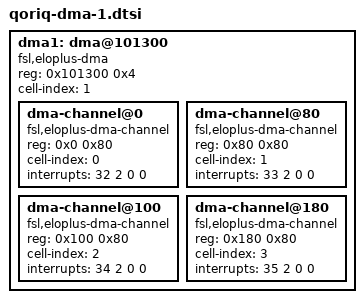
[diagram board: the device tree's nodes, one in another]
/*
 * QorIQ DMA device tree stub [ controller @ offset 0x101000 ]
 *
 * Copyright 2011 Freescale Semiconductor Inc.
 *
 * Redistribution and use in source and binary forms, with or without
 * modification, are permitted provided that the following conditions are met:
 *     * Redistributions of source code must retain the above copyright
 *       notice, this list of conditions and the following disclaimer.
 *     * Redistributions in binary form must reproduce the above copyright
 *       notice, this list of conditions and the following disclaimer in the
 *       documentation and/or other materials provided with the distribution.
 *     * Neither the name of Freescale Semiconductor nor the
 *       names of its contributors may be used to endorse or promote products
 *       derived from this software without specific prior written permission.
 *
 *
 * ALTERNATIVELY, this software may be distributed under the terms of the
 * GNU General Public License ("GPL") as published by the Free Software
 * Foundation, either version 2 of that License or (at your option) any
 * later version.
 *
 * THIS SOFTWARE IS PROVIDED BY Freescale Semiconductor ``AS IS'' AND ANY
 * EXPRESS OR IMPLIED WARRANTIES, INCLUDING, BUT NOT LIMITED TO, THE IMPLIED
 * WARRANTIES OF MERCHANTABILITY AND FITNESS FOR A PARTICULAR PURPOSE ARE
 * DISCLAIMED. IN NO EVENT SHALL Freescale Semiconductor BE LIABLE FOR ANY
 * DIRECT, INDIRECT, INCIDENTAL, SPECIAL, EXEMPLARY, OR CONSEQUENTIAL DAMAGES
 * (INCLUDING, BUT NOT LIMITED TO, PROCUREMENT OF SUBSTITUTE GOODS OR SERVICES;
 * LOSS OF USE, DATA, OR PROFITS; OR BUSINESS INTERRUPTION) HOWEVER CAUSED AND
 * ON ANY THEORY OF LIABILITY, WHETHER IN CONTRACT, STRICT LIABILITY, OR TORT
 * (INCLUDING NEGLIGENCE OR OTHERWISE) ARISING IN ANY WAY OUT OF THE USE OF THIS
 * SOFTWARE, EVEN IF ADVISED OF THE POSSIBILITY OF SUCH DAMAGE.
 */

dma1: dma@101300 {
	#address-cells = <1>;
	#size-cells = <1>;
	compatible = "fsl,eloplus-dma";
	reg = <0x101300 0x4>;
	ranges = <0x0 0x101100 0x200>;
	cell-index = <1>;
	dma-channel@0 {
		compatible = "fsl,eloplus-dma-channel";
		reg = <0x0 0x80>;
		cell-index = <0>;
		interrupts = <32 2 0 0>;
	};
	dma-channel@80 {
		compatible = "fsl,eloplus-dma-channel";
		reg = <0x80 0x80>;
		cell-index = <1>;
		interrupts = <33 2 0 0>;
	};
	dma-channel@100 {
		compatible = "fsl,eloplus-dma-channel";
		reg = <0x100 0x80>;
		cell-index = <2>;
		interrupts = <34 2 0 0>;
	};
	dma-channel@180 {
		compatible = "fsl,eloplus-dma-channel";
		reg = <0x180 0x80>;
		cell-index = <3>;
		interrupts = <35 2 0 0>;
	};
};
